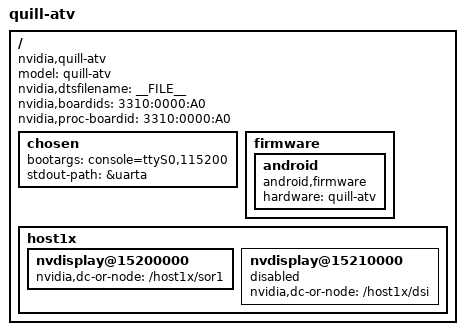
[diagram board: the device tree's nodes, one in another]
/*

 * tegra186-priv-quill-atv-p3310-1000-a00-00-base.dts Quill A00 Board
 *
 * Copyright (c) 2016, NVIDIA CORPORATION.  All rights reserved.
 *
 * This program is free software; you can redistribute it and/or modify
 * it under the terms of the GNU General Public License as published by
 * the Free Software Foundation; version 2 of the License.
 *
 * This program is distributed in the hope that it will be useful, but WITHOUT
 * ANY WARRANTY; without even the implied warranty of MERCHANTABILITY or
 * FITNESS FOR A PARTICULAR PURPOSE.  See the GNU General Public License for
 * more details.
 */

#include "tegra186-priv-quill-p3310-1000-a00-00-base.dts"

/ {
	model = "quill-atv";
	compatible = "nvidia,quill-atv", "nvidia,tegra186";

	nvidia,dtsfilename = __FILE__;
	nvidia,boardids = "3310:0000:A0";
	nvidia,proc-boardid = "3310:0000:A0";

	chosen {
		bootargs ="console=ttyS0,115200";
		stdout-path = &uarta;
	};

	firmware {
		android {
			compatible = "android,firmware";
			hardware = "quill-atv";
		};
	};

	host1x {
		nvdisplay@15200000 {
			status = "okay";
			nvidia,dc-or-node = "/host1x/sor1";
		};
		nvdisplay@15210000 {
			status = "disabled";
			nvidia,dc-or-node = "/host1x/dsi";
		};
	};
};
